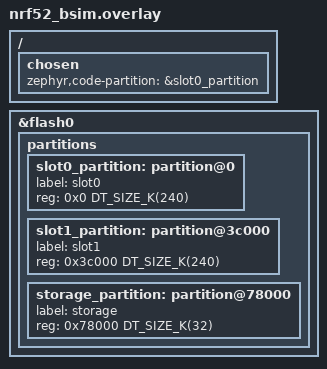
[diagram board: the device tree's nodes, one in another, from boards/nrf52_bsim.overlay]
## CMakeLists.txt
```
# Copyright (c) 2025 Golioth, Inc.
#
# SPDX-License-Identifier: Apache-2.0

cmake_minimum_required(VERSION 3.20.0)

find_package(Zephyr REQUIRED HINTS $ENV{ZEPHYR_BASE})
project(serial_device_example)

target_sources(app PRIVATE
  src/main.c
  src/credentials.c
  src/fatal_error.c
)
```

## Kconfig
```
# Copyright (c) 2025 Golioth, Inc.
#
# SPDX-License-Identifier: Apache-2.0

config NCS_APPLICATION_BOOT_BANNER_STRING
    string
    default "Pouch SPI Serial Device Example"

source "$ZEPHYR_BASE/Kconfig"

config EXAMPLE_SYNC_PERIOD_S
    int "Sync Period"
    default 10
    help
      The time, in seconds, after a sync to wait before requesting a sync from
      a gateway.

config EXAMPLE_CREDENTIALS_DIR
    string "Directory containing credentials"
    default "/lfs1/credentials"
    help
      Directory on mounted file system containing credentials.

config EXAMPLE_POUCH_DEVICE_CRT_FILENAME
    string "Pouch device crt filename in filesystem"
    default "crt.der"
    help
      The filename used to store the pouch device certificate in the filesystem.

config EXAMPLE_POUCH_DEVICE_KEY_FILENAME
    string "Pouch device key filename in filesystem"
    default "key.der"
    help
      The filename used to store the pouch device private key in the filesystem.
```

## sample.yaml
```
sample:
  name: Pouch SPI Serial Device
common:
  build_only: true
  tags: spi
tests:
  pouch.serial_device.build:
    platform_allow:
      - nrf52840dk/nrf52840
    integration_platforms:
      - nrf52840dk/nrf52840
```

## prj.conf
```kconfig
# Copyright (c) 2026 Golioth, Inc.
#
# SPDX-License-Identifier: Apache-2.0

CONFIG_MAIN_STACK_SIZE=4096
CONFIG_SYSTEM_WORKQUEUE_STACK_SIZE=4096

# Turn off default options to reduce ROM usage
CONFIG_MBEDTLS_PKCS5_C=n

CONFIG_LOG=y
CONFIG_ZCBOR=y
CONFIG_REBOOT=y
CONFIG_SHELL=y

CONFIG_POUCH=y
CONFIG_SPI=y
CONFIG_POUCH_TRANSPORT_SERIAL=y

CONFIG_GOLIOTH=y
CONFIG_GOLIOTH_SETTINGS=y
CONFIG_GOLIOTH_OTA=y

# Enable flash operations
CONFIG_FLASH=y
CONFIG_FLASH_MAP=y

# Enable the LittleFS file system
CONFIG_FILE_SYSTEM=y
CONFIG_FILE_SYSTEM_LITTLEFS=y
CONFIG_FILE_SYSTEM_SHELL=y

CONFIG_MCUMGR=y
CONFIG_NET_BUF=y

# Enable console with mcumgr pass through
CONFIG_CONSOLE=y
CONFIG_UART_CONSOLE=y
CONFIG_UART_CONSOLE_MCUMGR=y

# Enable the shell mcumgr transport. This allows SMP messages to pass
# through the shell to the mgmt subsystem.
CONFIG_BASE64=y
CONFIG_CRC=y
CONFIG_MCUMGR_TRANSPORT_SHELL=y

# Enable mcumgr params to allow smpmgr to query device for its MTU
CONFIG_MCUMGR_GRP_OS=y
CONFIG_MCUMGR_GRP_OS_MCUMGR_PARAMS=y

# Enable file system commands
CONFIG_MCUMGR_GRP_FS=y

CONFIG_MCUMGR_MGMT_NOTIFICATION_HOOKS=y
CONFIG_MCUMGR_GRP_FS_FILE_ACCESS_HOOK=y
```

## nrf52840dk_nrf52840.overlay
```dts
/*
 * Copyright (c) 2026 Golioth, Inc.
 */

&spi1 {
	compatible = "nordic,nrf-spis";
	status = "okay";
	def-char = < 0 >;
	overrun-character = < 0 >;

	pouch_serial: pouch-serial@0 {
		compatible = "golioth,pouch-device";
		reg = <0>;
		spi-max-frequency = <1000000>;
		data-ready-gpios = < &gpio0 28 GPIO_ACTIVE_HIGH >;
	};
};

&spi1_default {
	group1 {
		psels = <NRF_PSEL(SPIS_SCK, 0, 27)>,
		        <NRF_PSEL(SPIS_MOSI, 0, 26)>,
		        <NRF_PSEL(SPIS_MISO, 0, 29)>,
		        <NRF_PSEL(SPIS_CSN, 0, 5)>;
	};
};

&spi1_sleep {
	group1 {
		psels = <NRF_PSEL(SPIS_SCK, 0, 27)>,
		        <NRF_PSEL(SPIS_MOSI, 0, 26)>,
		        <NRF_PSEL(SPIS_MISO, 0, 29)>,
		        <NRF_PSEL(SPIS_CSN, 0, 5)>;
	};
};
```

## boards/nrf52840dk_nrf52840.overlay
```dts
/*
 * Copyright (c) 2026 Golioth, Inc.
 */

/* A board overlay replaces app.overlay, which mounts the credentials file system */
#include "../app.overlay"

&spi1 {
	compatible = "nordic,nrf-spis";
	status = "okay";
	def-char = < 0 >;
	overrun-character = < 0 >;

	pouch_serial: pouch-serial@0 {
		compatible = "golioth,pouch-device";
		reg = <0>;
		spi-max-frequency = <1000000>;
		data-ready-gpios = < &gpio0 28 GPIO_ACTIVE_HIGH >;
	};
};

&spi1_default {
	group1 {
		psels = <NRF_PSEL(SPIS_SCK, 0, 27)>,
		        <NRF_PSEL(SPIS_MOSI, 0, 26)>,
		        <NRF_PSEL(SPIS_MISO, 0, 29)>,
		        <NRF_PSEL(SPIS_CSN, 0, 5)>;
	};
};

&spi1_sleep {
	group1 {
		psels = <NRF_PSEL(SPIS_SCK, 0, 27)>,
		        <NRF_PSEL(SPIS_MOSI, 0, 26)>,
		        <NRF_PSEL(SPIS_MISO, 0, 29)>,
		        <NRF_PSEL(SPIS_CSN, 0, 5)>;
	};
};
```

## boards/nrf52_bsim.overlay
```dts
/ {
	chosen {
		zephyr,code-partition = &slot0_partition;
	};
};

&flash0 {
	partitions {
		/delete-node/ partition@0;

		slot0_partition: partition@0 {
			label = "slot0";
			reg = <0x0 DT_SIZE_K(240)>;
		};

		slot1_partition: partition@3c000 {
			label = "slot1";
			reg = <0x3c000 DT_SIZE_K(240)>;
		};

		storage_partition: partition@78000 {
			label = "storage";
			reg = <0x78000 DT_SIZE_K(32)>;
		};
	};
};
```

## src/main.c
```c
/*
 * Copyright (c) 2025 Golioth
 *
 * SPDX-License-Identifier: Apache-2.0
 */

#include <zephyr/logging/log.h>
LOG_MODULE_REGISTER(main);

#include "credentials.h"

#include <zephyr/drivers/gpio.h>

#include <pouch/pouch.h>
#include <pouch/events.h>
#include <pouch/uplink.h>
#include <pouch/downlink.h>
#include <pouch/transport/serial/device.h>

#include <golioth/settings_callbacks.h>

#include <app_version.h>

static const struct gpio_dt_spec led = GPIO_DT_SPEC_GET_OR(DT_ALIAS(led0), gpios, {});

static void do_sync(struct k_work *work)
{
    LOG_INF("SYNC");
    pouch_serial_device_sync();
    k_work_schedule(k_work_delayable_from_work(work), K_SECONDS(CONFIG_EXAMPLE_SYNC_PERIOD_S));
}

static K_WORK_DELAYABLE_DEFINE(sync, do_sync);

/**
 * Push timeseries application data to the cloud on every uplink
 */
static void do_uplink(void)
{
    LOG_INF("Sending uplink data\n");
    const char *data = "{\"temp\":22}";
    pouch_uplink_entry_write(".s/sensor",
                             POUCH_CONTENT_TYPE_JSON,
                             data,
                             strlen(data),
                             POUCH_FOREVER);
}

POUCH_UPLINK_HANDLER(do_uplink);

/**
 * Settings handler for the "LED" setting.
 *
 * The settings handler gets called when the Settings service
 * receives a new value for the registered setting.
 */
static int led_setting_cb(bool new_value)
{
    LOG_INF("Received LED setting: %d", (int) new_value);

    if (DT_HAS_ALIAS(led0))
    {
        gpio_pin_set_dt(&led, new_value ? 1 : 0);
    }

    return 0;
}

GOLIOTH_SETTINGS_HANDLER(LED, led_setting_cb);

/**
 * Setup pouch stack.
 *
 * Loads credentials and initializes pouch.
 */
static int setup_pouch(void)
{
    struct pouch_config config = {0};

    int err = load_certificate(&config.certificate);
    if (err)
    {
        LOG_ERR("Failed to load certificate (err %d)", err);
        return err;
    }

    config.private_key = load_private_key();
    if (config.private_key == PSA_KEY_ID_NULL)
    {
        LOG_ERR("Failed to load private key");
        return -ENOENT;
    }

    LOG_INF("Credentials loaded");

    err = pouch_init(&config);
    if (err)
    {
        LOG_ERR("Pouch init failed (err %d)", err);
        return err;
    }

    LOG_INF("Pouch initialized");
    return 0;
}

/**
 * Initialize LED.
 *
 * If the LED can't be initialized, we'll log it, but not crash out.
 * The example can still work without it.
 */
static void setup_led(void)
{
    if (!DT_HAS_ALIAS(led0))
    {
        return;
    }

    int err = gpio_pin_configure_dt(&led, GPIO_OUTPUT_ACTIVE);
    if (err < 0)
    {
        LOG_WRN("Could not initialize LED");
    }
}

int main(void)
{
    LOG_INF("Pouch SDK Version: " STRINGIFY(APP_BUILD_VERSION));
    LOG_INF("Pouch Protocol Version: %d", POUCH_VERSION);

    int err = setup_pouch();
    if (err)
    {
        return err;
    }

    setup_led();

    k_work_schedule(&sync, K_NO_WAIT);

    return 0;
}
```

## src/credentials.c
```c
/*
 * Copyright (c) 2025 Golioth, Inc.
 *
 * SPDX-License-Identifier: Apache-2.0
 */
#include <stdlib.h>
#include <zephyr/fs/fs.h>
#include <zephyr/init.h>
#include <pouch/pouch.h>
#include <mbedtls/pk.h>
#include <mbedtls/psa_util.h>

#include <zephyr/logging/log.h>
LOG_MODULE_REGISTER(credentials);

#define CERT_DIR CONFIG_EXAMPLE_CREDENTIALS_DIR
#define CERT_FILE CERT_DIR "/" CONFIG_EXAMPLE_POUCH_DEVICE_CRT_FILENAME
#define KEY_FILE CERT_DIR "/" CONFIG_EXAMPLE_POUCH_DEVICE_KEY_FILENAME

/** Load the raw private key data into PSA */
static psa_key_id_t import_raw_pk(const uint8_t *private_key, size_t size)
{
    mbedtls_pk_context pk;
    mbedtls_pk_init(&pk);
    int err = mbedtls_pk_parse_key(&pk, private_key, size, NULL, 0);
    if (err)
    {
        LOG_ERR("Failed to parse key: -0x%x", -err);
        return PSA_KEY_ID_NULL;
    }

    psa_key_attributes_t attrs = PSA_KEY_ATTRIBUTES_INIT;

    psa_set_key_algorithm(&attrs, PSA_ALG_ECDH);
    psa_set_key_type(&attrs, PSA_KEY_TYPE_ECC_KEY_PAIR(PSA_ECC_FAMILY_SECP_R1));
    psa_set_key_usage_flags(&attrs, PSA_KEY_USAGE_DERIVE);

    psa_key_id_t key_id;
    err = mbedtls_pk_import_into_psa(&pk, &attrs, &key_id);
    if (err)
    {
        LOG_ERR("Failed to import private key: -0x%x", -err);
        return PSA_KEY_ID_NULL;
    }

    return key_id;
}

static int ensure_credentials_dir(void)
{
    struct fs_dirent dirent;

    int err = fs_stat(CERT_DIR, &dirent);
    if (err == -ENOENT)
    {
        err = fs_mkdir(CERT_DIR);
    }

    if (err)
    {
        LOG_ERR("Failed to create credentials dir: %d", err);
    }

    return err;
}

/* Run after filesystem mounts, before SMP provisioning */
SYS_INIT(ensure_credentials_dir, APPLICATION, 85);

static ssize_t get_file_size(const char *path)
{
    struct fs_dirent dirent;

    int err = fs_stat(path, &dirent);

    if (err < 0)
    {
        return err;
    }
    if (dirent.type != FS_DIR_ENTRY_FILE)
    {
        return -EISDIR;
    }

    return dirent.size;
}

static ssize_t read_file(const char *path, uint8_t **out)
{
    ssize_t size = get_file_size(path);
    if (size <= 0)
    {
        return size;
    }

    uint8_t *buf = malloc(size);
    if (buf == NULL)
    {
        return -ENOMEM;
    }

    struct fs_file_t file;
    fs_file_t_init(&file);

    int err = fs_open(&file, path, FS_O_READ);
    if (err)
    {
        LOG_ERR("Could not open %s, err: %d", path, err);
        free(buf);
        return err;
    }

    size = fs_read(&file, buf, size);
    if (size < 0)
    {
        LOG_ERR("Could not read %s, err: %d", path, size);
        free(buf);
        goto finish;
    }

    LOG_DBG("Read %d bytes from %s", size, path);

    *out = buf;

finish:
    fs_close(&file);
    return size;
}

psa_key_id_t load_private_key(void)
{
    uint8_t *buf;
    ssize_t size = read_file(KEY_FILE, &buf);
    if (size < 0)
    {
        return PSA_KEY_ID_NULL;
    }

    psa_key_id_t key_id = import_raw_pk(buf, size);
    free(buf);
    return key_id;
}

int load_certificate(struct pouch_cert *cert)
{
    uint8_t *buf;
    ssize_t size = read_file(CERT_FILE, &buf);
    if (size < 0)
    {
        return size;
    }

    cert->buffer = buf;
    cert->size = size;

    LOG_DBG("Read certificate (%d bytes)", size);

    return 0;
}

void free_certificate(struct pouch_cert *cert)
{
    free((void *) cert->buffer);
}
```

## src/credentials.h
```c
/*
 * Copyright (c) 2025 Golioth, Inc.
 *
 * SPDX-License-Identifier: Apache-2.0
 */
#pragma once
#include <psa/crypto.h>
#include <pouch/types.h>

/**
 * Import the device private key into PSA
 *
 * @returns The assigned PSA key ID for the device's private key, or @c PSA_KEY_ID_NULL if the
 * private key couldn't be loaded.
 */
psa_key_id_t load_private_key(void);

/**
 * Load the device certificate.
 */
int load_certificate(struct pouch_cert *cert);

/** Free the device certificate. */
void free_certificate(struct pouch_cert *cert);
```
